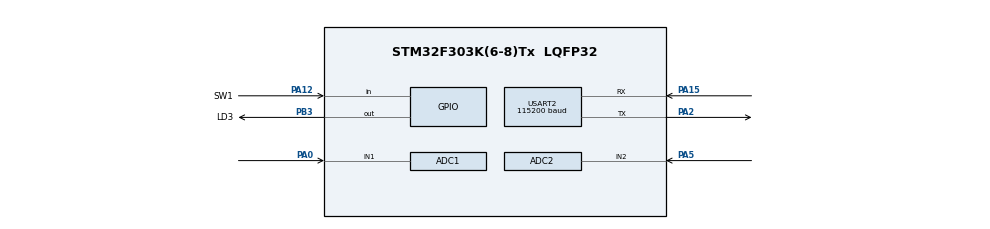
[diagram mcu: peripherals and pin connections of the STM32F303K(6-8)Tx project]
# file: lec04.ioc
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ADC1.Channel-0\#ChannelRegularConversion=ADC_CHANNEL_1
ADC1.ClockPrescaler=ADC_CLOCK_ASYNC_DIV1
ADC1.ContinuousConvMode=ENABLE
ADC1.NbrOfConversionFlag=1
ADC1.Offset-0\#ChannelRegularConversion=0
ADC1.OffsetNumber-0\#ChannelRegularConversion=ADC_OFFSET_NONE
ADC1.Rank-0\#ChannelRegularConversion=1
ADC1.SamplingTime-0\#ChannelRegularConversion=ADC_SAMPLETIME_1CYCLE_5
ADC1.SubFamily=STM32F303x8
ADC1.master=1
ADC2.Channel-1\#ChannelRegularConversion=ADC_CHANNEL_2
ADC2.ContinuousConvMode=ENABLE
ADC2.NbrOfConversion=1
ADC2.NbrOfConversionFlag=1
ADC2.Offset-1\#ChannelRegularConversion=0
ADC2.OffsetNumber-1\#ChannelRegularConversion=ADC_OFFSET_NONE
ADC2.Rank-1\#ChannelRegularConversion=1
ADC2.SamplingTime-1\#ChannelRegularConversion=ADC_SAMPLETIME_1CYCLE_5
ADC2.SubFamily=STM32F303x8
Dma.ADC1.0.Direction=DMA_PERIPH_TO_MEMORY
Dma.ADC1.0.Instance=DMA1_Channel1
Dma.ADC1.0.MemDataAlignment=DMA_MDATAALIGN_HALFWORD
Dma.ADC1.0.MemInc=DMA_MINC_ENABLE
Dma.ADC1.0.Mode=DMA_CIRCULAR
Dma.ADC1.0.PeriphDataAlignment=DMA_PDATAALIGN_HALFWORD
Dma.ADC1.0.PeriphInc=DMA_PINC_DISABLE
Dma.ADC1.0.Priority=DMA_PRIORITY_LOW
Dma.ADC2.1.Direction=DMA_PERIPH_TO_MEMORY
Dma.ADC2.1.Instance=DMA1_Channel2
Dma.ADC2.1.MemDataAlignment=DMA_MDATAALIGN_HALFWORD
Dma.ADC2.1.MemInc=DMA_MINC_ENABLE
Dma.ADC2.1.Mode=DMA_NORMAL
Dma.ADC2.1.PeriphDataAlignment=DMA_PDATAALIGN_HALFWORD
Dma.ADC2.1.PeriphInc=DMA_PINC_DISABLE
Dma.ADC2.1.Priority=DMA_PRIORITY_LOW
Dma.Request0=ADC1
Dma.Request1=ADC2
Mcu.Family=STM32F3
Mcu.Name=STM32F303K(6-8)Tx
Mcu.Package=LQFP32
NVIC.DMA1_Channel1_IRQn=true\:0\:0\:false\:false\:true\:false\:true
NVIC.DMA1_Channel2_IRQn=true\:0\:0\:false\:false\:true\:false\:true
NVIC.PriorityGroup=NVIC_PRIORITYGROUP_4
PA0.Mode=IN1-Single-Ended
PA0.Signal=ADC1_IN1
PA12.GPIO_Label=SW1
PA12.Signal=GPIO_Input
PA15.Mode=Asynchronous
PA15.Signal=USART2_RX
PA2.Mode=Asynchronous
PA2.Signal=USART2_TX
PA5.Mode=IN2-Single-Ended
PA5.Signal=ADC2_IN2
PB3.GPIO_Label=LD3
PB3.Signal=GPIO_Output
ProjectManager.HeapSize=0x200
ProjectManager.StackSize=0x400
ProjectManager.TargetToolchain=SW4STM32
RCC.AHBFreq_Value=64000000
RCC.APB1CLKDivider=RCC_HCLK_DIV2
RCC.APB1Freq_Value=32000000
RCC.APB1TimFreq_Value=64000000
RCC.APB2Freq_Value=64000000
RCC.APB2TimFreq_Value=64000000
RCC.CortexFreq_Value=64000000
RCC.HCLKFreq_Value=64000000
RCC.HSE_VALUE=8000000
RCC.HSI_VALUE=8000000
RCC.PLLMUL=RCC_PLL_MUL16
RCC.SYSCLKFreq_VALUE=64000000
RCC.SYSCLKSourceVirtual=RCC_SYSCLKSOURCE_PLLCLK
USART2.BaudRate=115200
USART2.VirtualMode-Asynchronous=VM_ASYNC
board=custom

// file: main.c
/* USER CODE BEGIN Header */
/**
 ******************************************************************************
 * @file           : main.c
 * @brief          : Main program body
 ******************************************************************************
 * @attention
 *
 * <h2><center>&copy; Copyright (c) 2020 STMicroelectronics.
 * All rights reserved.</center></h2>
 *
 * This software component is licensed by ST under BSD 3-Clause license,
 * the "License"; You may not use this file except in compliance with the
 * License. You may obtain a copy of the License at:
 *                        opensource.org/licenses/BSD-3-Clause
 *
 ******************************************************************************
 */
/* USER CODE END Header */

#include "main.h"

ADC_HandleTypeDef hadc1;
ADC_HandleTypeDef hadc2;

UART_HandleTypeDef huart2;

void SystemClock_Config(void);
static void MX_GPIO_Init(void);
static void MX_USART2_UART_Init(void);
static void MX_ADC1_Init(void);
static void MX_ADC2_Init(void);

int main(void)
{

  /* MCU Configuration--------------------------------------------------------*/

  /* Reset of all peripherals, Initializes the Flash interface and the Systick. */
  HAL_Init();

  /* Configure the system clock */
  SystemClock_Config();

  /* Initialize all configured peripherals */
  MX_GPIO_Init();
  MX_USART2_UART_Init();
  MX_ADC1_Init();
  MX_ADC2_Init();

  /* Infinite loop */
  /* USER CODE BEGIN WHILE */
	HAL_ADCEx_Calibration_Start(&hadc1, ADC_SINGLE_ENDED);
	HAL_ADC_Start(&hadc1);
	HAL_ADCEx_Calibration_Start(&hadc2, ADC_SINGLE_ENDED);
	HAL_ADC_Start(&hadc2);
	uint32_t adc1_val = 0;
	uint32_t adc2_val = 0;
	uint8_t  buf[20] = {};
	while (1) {
		adc1_val = HAL_ADC_GetValue(&hadc1);
		adc2_val = HAL_ADC_GetValue(&hadc2);
		sprintf(buf , "1 : %d 2 : %d\n\r" , adc1_val , adc2_val );
		HAL_UART_Transmit( &huart2 , buf , sizeof(buf) , 0xffff);
		HAL_Delay(1000);
    /* USER CODE END WHILE */

    /* USER CODE BEGIN 3 */
	}
	HAL_ADC_Stop(&hadc1);

  /* USER CODE END 3 */
}

void SystemClock_Config(void)
{
  RCC_OscInitTypeDef RCC_OscInitStruct = {0};
  RCC_ClkInitTypeDef RCC_ClkInitStruct = {0};
  RCC_PeriphCLKInitTypeDef PeriphClkInit = {0};

  /** Initializes the CPU, AHB and APB busses clocks
  */
  RCC_OscInitStruct.OscillatorType = RCC_OSCILLATORTYPE_HSI;
  RCC_OscInitStruct.HSIState = RCC_HSI_ON;
  RCC_OscInitStruct.HSICalibrationValue = RCC_HSICALIBRATION_DEFAULT;
  RCC_OscInitStruct.PLL.PLLState = RCC_PLL_ON;
  RCC_OscInitStruct.PLL.PLLSource = RCC_PLLSOURCE_HSI;
  RCC_OscInitStruct.PLL.PLLMUL = RCC_PLL_MUL4;
  if (HAL_RCC_OscConfig(&RCC_OscInitStruct) != HAL_OK)
  {
    Error_Handler();
  }
  /** Initializes the CPU, AHB and APB busses clocks
  */
  RCC_ClkInitStruct.ClockType = RCC_CLOCKTYPE_HCLK|RCC_CLOCKTYPE_SYSCLK
                              |RCC_CLOCKTYPE_PCLK1|RCC_CLOCKTYPE_PCLK2;
  RCC_ClkInitStruct.SYSCLKSource = RCC_SYSCLKSOURCE_HSI;
  RCC_ClkInitStruct.AHBCLKDivider = RCC_SYSCLK_DIV1;
  RCC_ClkInitStruct.APB1CLKDivider = RCC_HCLK_DIV1;
  RCC_ClkInitStruct.APB2CLKDivider = RCC_HCLK_DIV1;

  if (HAL_RCC_ClockConfig(&RCC_ClkInitStruct, FLASH_LATENCY_0) != HAL_OK)
  {
    Error_Handler();
  }
  PeriphClkInit.PeriphClockSelection = RCC_PERIPHCLK_ADC12;
  PeriphClkInit.Adc12ClockSelection = RCC_ADC12PLLCLK_DIV1;
  if (HAL_RCCEx_PeriphCLKConfig(&PeriphClkInit) != HAL_OK)
  {
    Error_Handler();
  }
}

static void MX_ADC1_Init(void)
{

  ADC_MultiModeTypeDef multimode = {0};
  ADC_ChannelConfTypeDef sConfig = {0};

  /** Common config
  */
  hadc1.Instance = ADC1;
  hadc1.Init.ClockPrescaler = ADC_CLOCK_ASYNC_DIV1;
  hadc1.Init.Resolution = ADC_RESOLUTION_12B;
  hadc1.Init.ScanConvMode = ADC_SCAN_DISABLE;
  hadc1.Init.ContinuousConvMode = ENABLE;
  hadc1.Init.DiscontinuousConvMode = DISABLE;
  hadc1.Init.ExternalTrigConvEdge = ADC_EXTERNALTRIGCONVEDGE_NONE;
  hadc1.Init.ExternalTrigConv = ADC_SOFTWARE_START;
  hadc1.Init.DataAlign = ADC_DATAALIGN_RIGHT;
  hadc1.Init.NbrOfConversion = 1;
  hadc1.Init.DMAContinuousRequests = DISABLE;
  hadc1.Init.EOCSelection = ADC_EOC_SINGLE_CONV;
  hadc1.Init.LowPowerAutoWait = DISABLE;
  hadc1.Init.Overrun = ADC_OVR_DATA_OVERWRITTEN;
  if (HAL_ADC_Init(&hadc1) != HAL_OK)
  {
    Error_Handler();
  }
  /** Configure the ADC multi-mode
  */
  multimode.Mode = ADC_MODE_INDEPENDENT;
  if (HAL_ADCEx_MultiModeConfigChannel(&hadc1, &multimode) != HAL_OK)
  {
    Error_Handler();
  }
  /** Configure Regular Channel
  */
  sConfig.Channel = ADC_CHANNEL_1;
  sConfig.Rank = ADC_REGULAR_RANK_1;
  sConfig.SingleDiff = ADC_SINGLE_ENDED;
  sConfig.SamplingTime = ADC_SAMPLETIME_1CYCLE_5;
  sConfig.OffsetNumber = ADC_OFFSET_NONE;
  sConfig.Offset = 0;
  if (HAL_ADC_ConfigChannel(&hadc1, &sConfig) != HAL_OK)
  {
    Error_Handler();
  }

}

static void MX_ADC2_Init(void)
{

  ADC_ChannelConfTypeDef sConfig = {0};

  /** Common config
  */
  hadc2.Instance = ADC2;
  hadc2.Init.ClockPrescaler = ADC_CLOCK_ASYNC_DIV1;
  hadc2.Init.Resolution = ADC_RESOLUTION_12B;
  hadc2.Init.ScanConvMode = ADC_SCAN_DISABLE;
  hadc2.Init.ContinuousConvMode = ENABLE;
  hadc2.Init.DiscontinuousConvMode = DISABLE;
  hadc2.Init.ExternalTrigConvEdge = ADC_EXTERNALTRIGCONVEDGE_NONE;
  hadc2.Init.ExternalTrigConv = ADC_SOFTWARE_START;
  hadc2.Init.DataAlign = ADC_DATAALIGN_RIGHT;
  hadc2.Init.NbrOfConversion = 1;
  hadc2.Init.DMAContinuousRequests = DISABLE;
  hadc2.Init.EOCSelection = ADC_EOC_SINGLE_CONV;
  hadc2.Init.LowPowerAutoWait = DISABLE;
  hadc2.Init.Overrun = ADC_OVR_DATA_OVERWRITTEN;
  if (HAL_ADC_Init(&hadc2) != HAL_OK)
  {
    Error_Handler();
  }
  /** Configure Regular Channel
  */
  sConfig.Channel = ADC_CHANNEL_2;
  sConfig.Rank = ADC_REGULAR_RANK_1;
  sConfig.SingleDiff = ADC_SINGLE_ENDED;
  sConfig.SamplingTime = ADC_SAMPLETIME_1CYCLE_5;
  sConfig.OffsetNumber = ADC_OFFSET_NONE;
  sConfig.Offset = 0;
  if (HAL_ADC_ConfigChannel(&hadc2, &sConfig) != HAL_OK)
  {
    Error_Handler();
  }

}

static void MX_USART2_UART_Init(void)
{

  huart2.Instance = USART2;
  huart2.Init.BaudRate = 115200;
  huart2.Init.WordLength = UART_WORDLENGTH_8B;
  huart2.Init.StopBits = UART_STOPBITS_1;
  huart2.Init.Parity = UART_PARITY_NONE;
  huart2.Init.Mode = UART_MODE_TX_RX;
  huart2.Init.HwFlowCtl = UART_HWCONTROL_NONE;
  huart2.Init.OverSampling = UART_OVERSAMPLING_16;
  huart2.Init.OneBitSampling = UART_ONE_BIT_SAMPLE_DISABLE;
  huart2.AdvancedInit.AdvFeatureInit = UART_ADVFEATURE_NO_INIT;
  if (HAL_UART_Init(&huart2) != HAL_OK)
  {
    Error_Handler();
  }

}

static void MX_GPIO_Init(void)
{
  GPIO_InitTypeDef GPIO_InitStruct = {0};

  /* GPIO Ports Clock Enable */
  __HAL_RCC_GPIOF_CLK_ENABLE();
  __HAL_RCC_GPIOA_CLK_ENABLE();
  __HAL_RCC_GPIOB_CLK_ENABLE();

  /*Configure GPIO pin Output Level */
  HAL_GPIO_WritePin(SW_GPIO_Port, SW_Pin, GPIO_PIN_RESET);

  /*Configure GPIO pin Output Level */
  HAL_GPIO_WritePin(LD3_GPIO_Port, LD3_Pin, GPIO_PIN_RESET);

  /*Configure GPIO pin : SW_Pin */
  GPIO_InitStruct.Pin = SW_Pin;
  GPIO_InitStruct.Mode = GPIO_MODE_OUTPUT_PP;
  GPIO_InitStruct.Pull = GPIO_NOPULL;
  GPIO_InitStruct.Speed = GPIO_SPEED_FREQ_LOW;
  HAL_GPIO_Init(SW_GPIO_Port, &GPIO_InitStruct);

  /*Configure GPIO pin : LD3_Pin */
  GPIO_InitStruct.Pin = LD3_Pin;
  GPIO_InitStruct.Mode = GPIO_MODE_OUTPUT_PP;
  GPIO_InitStruct.Pull = GPIO_NOPULL;
  GPIO_InitStruct.Speed = GPIO_SPEED_FREQ_LOW;
  HAL_GPIO_Init(LD3_GPIO_Port, &GPIO_InitStruct);

}

void Error_Handler(void)
{
}

/************************ (C) COPYRIGHT STMicroelectronics *****END OF FILE****/
